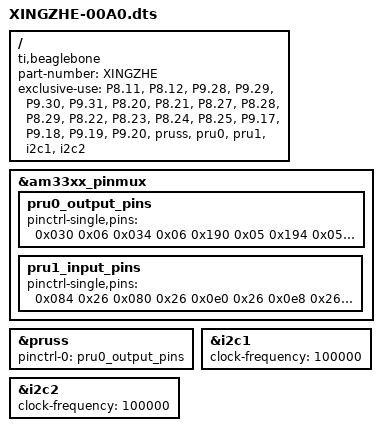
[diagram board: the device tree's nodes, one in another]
/dts-v1/;
/plugin/;

/ {
    compatible = "ti,beaglebone", "ti,beaglebone-black";

    /* identification */
    part-number = "XINGZHE";

    exclusive-use =
        "P8.11",    /* pr1_pru0_pru_r30_15 */
        "P8.12",    /* pr1_pru0_pru_r30_14 */
        "P9.28",    /* pr1_pru0_pru_r30_3 */
        "P9.29",    /* pr1_pru0_pru_r30_1 */
        "P9.30",    /* pr1_pru0_pru_r30_2 */
        "P9.31",    /* pr1_pru0_pru_r30_0 */

        "P8.20",    /* pr1_pru1_pru_r31_13 */
        "P8.21",    /* pr1_pru1_pru_r31_12 */
        "P8.27",    /* pr1_pru1_pru_r31_8 */
        "P8.28",    /* pr1_pru1_pru_r31_10 */
        "P8.29",    /* pr1_pru1_pru_r31_9 */

        "P8.22",    /* motor, enable */
        "P8.23",    /* motor, enable */
        "P8.24",    /* motor, enable */
        "P8.25",    /* motor, enable */

        "P9.17",    /*I2C1_SCL*/
        "P9.18",    /*I2C1_SDA*/
        "P9.19",    /*I2C2_SCL*/
        "P9.20",    /*I2C2_SDA*/

        "pruss",
        "pru0",
        "pru1",
        "i2c1",
        "i2c2";


    fragment@0 {
        target = <&am33xx_pinmux>;
        __overlay__ {
            pru0_output_pins: pru0_output_pins {
                pinctrl-single,pins = <
					0x030 0x06  /* P8_12 to PRU output */
					0x034 0x06  /* P8_11 to PRU output */
					0x190 0x05  /* P9_31 to PRU output */
                    0x194 0x05  /* P9_29 to PRU output */
					0x198 0x05  /* P9_30 to PRU output */
					0x19C 0x05  /* P9_28 to PRU output */
                >;
            };
            pru1_input_pins: pru1_input_pins {
                pinctrl-single,pins = <
                    0x084 0x26  /* P8_20 to PRU input */
                    0x080 0x26  /* P8_21 to PRU input */
                    0x0e0 0x26  /* P8_27 to PRU input */  
                    0x0e8 0x26  /* P8_28 to PRU input */
                    0x0e4 0x26  /* P8_29 to PRU input */
                >;
            };
        };
    };

    fragment@1 {
        target = <&pruss>;
        __overlay__ {
			status = "okay";
			pinctrl-names = "default";
			pinctrl-0 = <&pru0_output_pins>;
		};
	};


    /****************************************
            I2C
    ****************************************/
    fragment@2 {
        target = <&i2c1>;   /* i2c1 is numbered correctly */
        __overlay__ {
            status = "okay";

            /* this is the configuration part */
            clock-frequency = <100000>;

            #address-cells = <1>;
            #size-cells = <0>;

            /* add any i2c devices on the bus here */
        };
    };

    fragment@3 {
        target = <&i2c2>;   /* i2c2 is numbered correctly */
        __overlay__ {
            status = "okay";

            /* this is the configuration part */
            clock-frequency = <100000>;

            #address-cells = <1>;
            #size-cells = <0>;

            /* add any i2c devices on the bus here */
        };
    };
};

